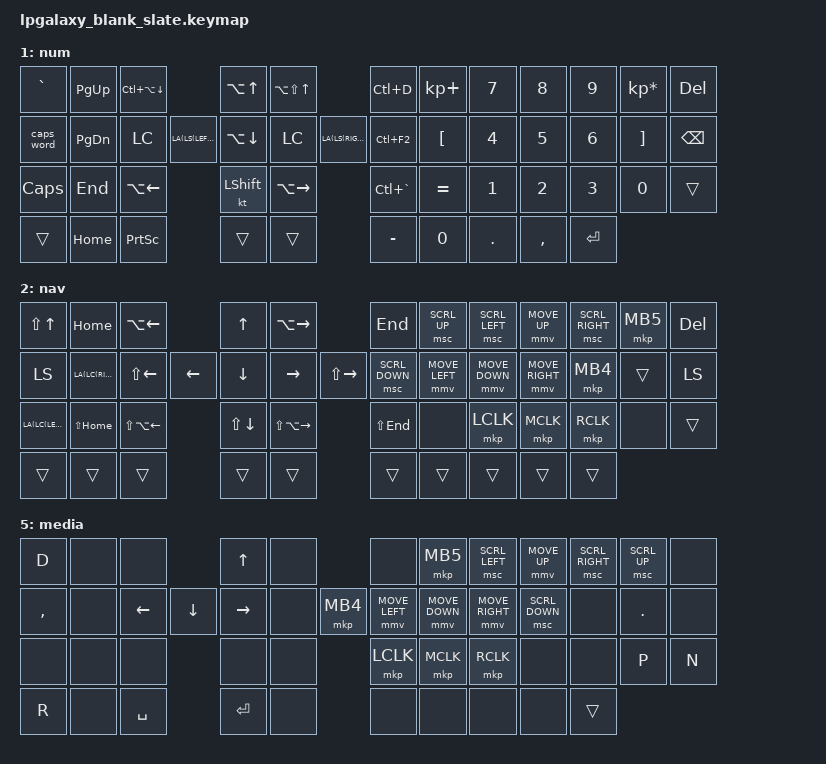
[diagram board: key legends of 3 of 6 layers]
/*
 * Copyright (c) 2020 The ZMK Contributors
 *
 * SPDX-License-Identifier: MIT
 */

#include <behaviors.dtsi>
#include <dt-bindings/zmk/bt.h>
#include <dt-bindings/zmk/keys.h>
#include <dt-bindings/zmk/outputs.h>
#include <dt-bindings/zmk/pointing.h>

/ {
    chosen { zmk,physical-layout = &layout_ortho_4x12_2x2u; };

    cond_layers { compatible = "zmk,conditional-layers"; };

    combos {
        compatible = "zmk,combos";

        bootloader {
            bindings = <&bootloader>;
            key-positions = <11 0>;
        };

        studiounlock {
            bindings = <&studio_unlock>;
            key-positions = <36 47>;
        };
    };

    keymap {
        compatible = "zmk,keymap";

        base_layer {
            bindings = <
&kp ESCAPE                  &kp Q     &kp W                  &kp E                &kp R         &kp T      &kp Y            &kp U             &kp I                         &kp O        &kp P      &kp BSPC
&lt 3 TAB                   &kp A     &kp S                  &kp D                &kp F         &kp G      &kp H            &kp J             &kp K                         &kp L        &kp SEMI   &kp SQT
&mt LSHFT LEFT_PARENTHESIS  &kp Z     &kp X                  &kp C                &kp V         &kp B      &kp N            &kp M             &kp COMMA                     &kp DOT      &kp SLASH  &mt RIGHT_SHIFT UP_ARROW
&kp LCTRL                   &kp LGUI  &mt LALT LEFT_BRACKET  &lt 3 RIGHT_BRACKET  &lt 1 RETURN  &kp SPACE  &lt 2 BACKSLASH  &lt 4 LEFT_ARROW  &mt RA(RC(RIGHT_SHIFT)) DOWN  &lt 5 RIGHT
            >;
        };

        num {
            bindings = <
&kp GRAVE   &kp PAGE_UP    &kp LC(LA(DOWN))      &kp LA(UP)      &kp LA(LS(UP))         &kp LC(D)      &kp KP_PLUS  &kp N7   &kp N8     &kp N9   &kp KP_ASTERISK  &kp DEL
&caps_word  &kp PAGE_DOWN  &kp LC(LA(LS(LEFT)))  &kp LA(DOWN)    &kp LC(LA(LS(RIGHT)))  &kp LC(F2)     &kp LBKT     &kp N4   &kp N5     &kp N6   &kp RBKT         &kp BACKSPACE
&kp CAPS    &kp END        &kp LA(LEFT_ARROW)    &kt LEFT_SHIFT  &kp LA(RIGHT)          &kp LC(GRAVE)  &kp EQUAL    &kp N1   &kp N2     &kp N3   &kp N0           &trans
&trans      &kp HOME       &kp PRINTSCREEN       &trans          &trans                 &kp MINUS      &kp N0       &kp DOT  &kp COMMA  &kp RET
            >;
        };

        nav {
            bindings = <
&kp LS(UP)             &kp HOME      &kp LA(LEFT)      &kp UP        &kp LA(RIGHT)      &kp END        &msc SCRL_UP    &msc SCRL_LEFT  &mmv MOVE_UP    &msc SCRL_RIGHT  &mkp MB5  &kp DELETE
&kp LS(LA(LC(RIGHT)))  &kp LS(LEFT)  &kp LEFT          &kp DOWN      &kp RIGHT          &kp LS(RIGHT)  &msc SCRL_DOWN  &mmv MOVE_LEFT  &mmv MOVE_DOWN  &mmv MOVE_RIGHT  &mkp MB4  &trans
&kp LS(LA(LC(LEFT)))   &kp LS(HOME)  &kp LS(LA(LEFT))  &kp LS(DOWN)  &kp LS(LA(RIGHT))  &kp LS(END)    &none           &mkp LCLK       &mkp MCLK       &mkp RCLK        &none     &trans
&trans                 &trans        &trans            &trans        &trans             &trans         &trans          &trans          &trans          &trans
            >;
        };

        sym {
            bindings = <
&kp TILDE    &kp N1  &kp N2  &kp N3  &kp N4  &kp N5          &kp LEFT_PARENTHESIS  &kp LS(AMPS)  &kp LS(STAR)   &kp LS(LPAR)   &kp RIGHT_PARENTHESIS  &kp DEL
&kp TAB      &kp N6  &kp N7  &kp N8  &kp N9  &kp N0          &kp LS(LBRC)          &kp LS(DLLR)  &kp LS(PRCNT)  &kp LS(CARET)  &kp LS(RBRC)           &kp BACKSPACE
&kp LS(TAB)  &none   &none   &none   &none   &kp PLUS        &kp LS(PLUS)          &kp LS(EXCL)  &kp LS(AT)     &kp LS(POUND)  &kp LS(QUESTION)       &kp PIPE
&trans       &trans  &kp N0  &trans  &trans  &kp UNDERSCORE  &trans                &trans        &trans         &trans
            >;
        };

        func {
            bindings = <
&kp F1          &kp F2        &kp F3        &kp F4        &kp F5          &kp F6        &kp F7  &kp F8  &kp F9  &kp F10      &kp F11  &kp F12
&bt BT_CLR_ALL  &out OUT_BLE  &out OUT_USB  &none         &studio_unlock  &none         &none   &none   &none   &none        &none    &none
&bt BT_CLR      &bt BT_SEL 0  &bt BT_SEL 1  &bt BT_SEL 2  &bt BT_SEL 3    &bt BT_SEL 4  &none   &none   &none   &bootloader  &none    &sys_reset
&none           &none         &none         &none         &none           &none         &none   &trans  &none   &soft_off
            >;
        };

        media {
            bindings = <
&kp D      &none  &none           &kp UP_ARROW  &none      &none      &mkp MB5  &msc SCRL_LEFT  &mmv MOVE_UP    &msc SCRL_RIGHT  &msc SCRL_UP    &none
&kp COMMA  &none  &kp LEFT_ARROW  &kp DOWN      &kp RIGHT  &none      &mkp MB4  &mmv MOVE_LEFT  &mmv MOVE_DOWN  &mmv MOVE_RIGHT  &msc SCRL_DOWN  &none
&kp DOT    &none  &none           &none         &none      &none      &none     &mkp LCLK       &mkp MCLK       &mkp RCLK        &none           &none
&kp P      &kp N  &kp R           &none         &kp SPACE  &kp ENTER  &none     &none           &none           &none            &none           &trans
            >;
        };
    };
};

// #define TBLE_ORTHO   1
// #define TBLE_MIT     1

#define TBLE_DUAL_2U 1
